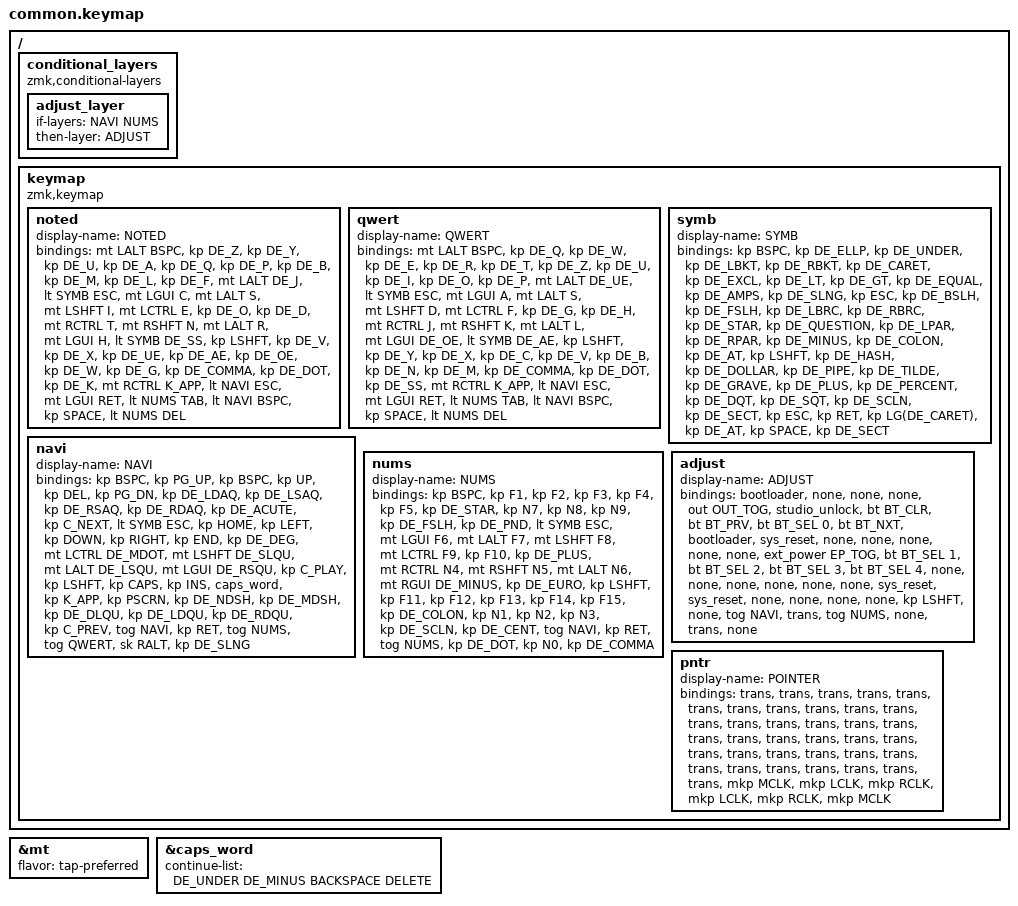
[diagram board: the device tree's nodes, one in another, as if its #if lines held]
#include <behaviors.dtsi>
#include <dt-bindings/zmk/bt.h>
#include <dt-bindings/zmk/ext_power.h>
#include <dt-bindings/zmk/keys.h>
#include <dt-bindings/zmk/outputs.h>
#include <dt-bindings/zmk/pointing.h>
#include "keys_de.h"

#define NOTED 0
#define QWERT 1
#define SYMB 2
#define NAVI 3
#define NUMS 4
#define ADJUST 5
#ifdef ZMK_CONFIG_ENABLE_POINTER_LAYER
#define PNTR 6
#endif

&mt {
    flavor = "tap-preferred";
};

&caps_word {
    continue-list = <DE_UNDER DE_MINUS BACKSPACE DELETE>;
};

/ {
    conditional_layers {
        compatible = "zmk,conditional-layers";
        adjust_layer {
            if-layers = <NAVI NUMS>;
            then-layer = <ADJUST>;
        };
    };

    keymap {
        compatible = "zmk,keymap";

        noted {
            display-name = "NOTED";
            bindings = <
                &mt LALT BSPC  &kp DE_Z   &kp DE_Y   &kp DE_U   &kp DE_A   &kp DE_Q     &kp DE_P   &kp DE_B   &kp DE_M   &kp DE_L   &kp DE_F   &mt LALT DE_J
                &lt SYMB ESC   &mt LGUI C &mt LALT S &mt LSHFT I &mt LCTRL E &kp DE_O    &kp DE_D   &mt RCTRL T &mt RSHFT N &mt LALT R &mt LGUI H &lt SYMB DE_SS
                &kp LSHFT      &kp DE_V   &kp DE_X   &kp DE_UE  &kp DE_AE  &kp DE_OE    &kp DE_W   &kp DE_G   &kp DE_COMMA &kp DE_DOT &kp DE_K   &mt RCTRL K_APP
                                                       &lt NAVI ESC &mt LGUI RET &lt NUMS TAB  &lt NAVI BSPC &kp SPACE &lt NUMS DEL
            >;
        };

        qwert {
            display-name = "QWERT";
            bindings = <
                &mt LALT BSPC  &kp DE_Q   &kp DE_W   &kp DE_E   &kp DE_R   &kp DE_T     &kp DE_Z   &kp DE_U   &kp DE_I   &kp DE_O   &kp DE_P   &mt LALT DE_UE
                &lt SYMB ESC   &mt LGUI A &mt LALT S &mt LSHFT D &mt LCTRL F &kp DE_G    &kp DE_H   &mt RCTRL J &mt RSHFT K &mt LALT L &mt LGUI DE_OE &lt SYMB DE_AE
                &kp LSHFT      &kp DE_Y   &kp DE_X   &kp DE_C   &kp DE_V   &kp DE_B     &kp DE_N   &kp DE_M   &kp DE_COMMA &kp DE_DOT &kp DE_SS  &mt RCTRL K_APP
                                                       &lt NAVI ESC &mt LGUI RET &lt NUMS TAB  &lt NAVI BSPC &kp SPACE &lt NUMS DEL
            >;
        };

        symb {
            display-name = "SYMB";
            bindings = <
                &kp BSPC      &kp DE_ELLP &kp DE_UNDER &kp DE_LBKT &kp DE_RBKT &kp DE_CARET  &kp DE_EXCL &kp DE_LT   &kp DE_GT   &kp DE_EQUAL &kp DE_AMPS &kp DE_SLNG
                &kp ESC       &kp DE_BSLH &kp DE_FSLH  &kp DE_LBRC &kp DE_RBRC &kp DE_STAR   &kp DE_QUESTION &kp DE_LPAR &kp DE_RPAR &kp DE_MINUS &kp DE_COLON &kp DE_AT
                &kp LSHFT     &kp DE_HASH &kp DE_DOLLAR &kp DE_PIPE &kp DE_TILDE &kp DE_GRAVE &kp DE_PLUS &kp DE_PERCENT &kp DE_DQT &kp DE_SQT &kp DE_SCLN &kp DE_SECT
                                                       &kp ESC &kp RET &kp LG(DE_CARET)  &kp DE_AT &kp SPACE &kp DE_SECT
            >;
        };

        navi {
            display-name = "NAVI";
            bindings = <
                &kp BSPC  &kp PG_UP &kp BSPC &kp UP   &kp DEL  &kp PG_DN   &kp DE_LDAQ &kp DE_LSAQ &kp DE_RSAQ &kp DE_RDAQ &kp DE_ACUTE &kp C_NEXT
                &lt SYMB ESC   &kp HOME &kp LEFT &kp DOWN &kp RIGHT &kp END    &kp DE_DEG  &mt LCTRL DE_MDOT &mt LSHFT DE_SLQU &mt LALT DE_LSQU &mt LGUI DE_RSQU &kp C_PLAY
                &kp LSHFT &kp CAPS &kp INS  &caps_word &kp K_APP &kp PSCRN &kp DE_NDSH &kp DE_MDSH &kp DE_DLQU &kp DE_LDQU &kp DE_RDQU &kp C_PREV
                                                    &tog NAVI &kp RET &tog NUMS  &tog QWERT &sk RALT &kp DE_SLNG
            >;
        };

        nums {
            display-name = "NUMS";
            bindings = <
                &kp BSPC  &kp F1   &kp F2   &kp F3   &kp F4   &kp F5     &kp DE_STAR &kp N7   &kp N8   &kp N9   &kp DE_FSLH &kp DE_PND
                &lt SYMB ESC   &mt LGUI F6 &mt LALT F7 &mt LSHFT F8 &mt LCTRL F9 &kp F10 &kp DE_PLUS &mt RCTRL N4 &mt RSHFT N5 &mt LALT N6 &mt RGUI DE_MINUS &kp DE_EURO
                &kp LSHFT &kp F11  &kp F12  &kp F13  &kp F14  &kp F15    &kp DE_COLON &kp N1 &kp N2 &kp N3 &kp DE_SCLN &kp DE_CENT
                                                    &tog NAVI &kp RET &tog NUMS  &kp DE_DOT &kp N0 &kp DE_COMMA
            >;
        };

        adjust {
            display-name = "ADJUST";
            bindings = <
                &bootloader &none &none &none &out OUT_TOG &studio_unlock  &bt BT_CLR &bt BT_PRV &bt BT_SEL 0 &bt BT_NXT &bootloader &sys_reset
                &none &none &none &none &none &ext_power EP_TOG              &bt BT_SEL 1 &bt BT_SEL 2 &bt BT_SEL 3 &bt BT_SEL 4 &none &none
                &none &none &none &none &sys_reset &sys_reset                &none &none &none &none &kp LSHFT &none
                                                    &tog NAVI &trans &tog NUMS  &none &trans &none
            >;
        };

#ifdef ZMK_CONFIG_ENABLE_POINTER_LAYER
        pntr {
            display-name = "POINTER";
            bindings = <
                &trans &trans &trans &trans &trans &trans  &trans &trans &trans &trans &trans &trans
                &trans &trans &trans &trans &trans &trans  &trans &trans &trans &trans &trans &trans
                &trans &trans &trans &trans &trans &trans  &trans &trans &trans &trans &trans &trans
                                                    &mkp MCLK &mkp LCLK &mkp RCLK  &mkp LCLK &mkp RCLK &mkp MCLK
            >;
        };
#endif
    };
};
